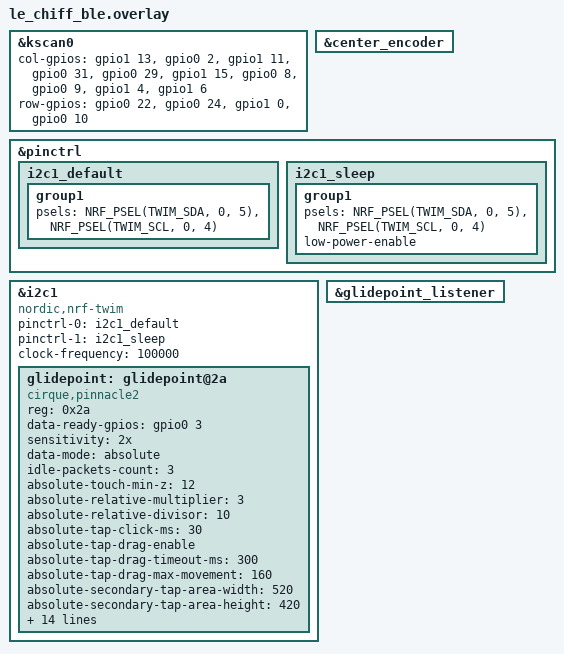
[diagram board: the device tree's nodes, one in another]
/*
 * Copyright (c) 2020 The ZMK Contributors
 *
 * SPDX-License-Identifier: MIT
 */

#include "le_chiff_ble.dtsi"
#include <behaviors/battery_history_request.dtsi>
#include <input/processors.dtsi>
#include <input/processors/runtime-input-processor.dtsi>

&kscan0 {
    col-gpios
        = <&gpio1 13 GPIO_ACTIVE_HIGH>
        , <&gpio0 2 GPIO_ACTIVE_HIGH>
        , <&gpio1 11 GPIO_ACTIVE_HIGH>
        , <&gpio0 31 GPIO_ACTIVE_HIGH>
        , <&gpio0 29 GPIO_ACTIVE_HIGH>
        , <&gpio1 15 GPIO_ACTIVE_HIGH>
        , <&gpio0 8 GPIO_ACTIVE_HIGH>
        , <&gpio0 9 GPIO_ACTIVE_HIGH>
        , <&gpio1 4 GPIO_ACTIVE_HIGH>
        , <&gpio1 6 GPIO_ACTIVE_HIGH>
        ;
    row-gpios
        = <&gpio0 22 (GPIO_ACTIVE_HIGH | GPIO_PULL_DOWN)>
        , <&gpio0 24 (GPIO_ACTIVE_HIGH | GPIO_PULL_DOWN)>
        , <&gpio1 0  (GPIO_ACTIVE_HIGH | GPIO_PULL_DOWN)>
        , <&gpio0 10 (GPIO_ACTIVE_HIGH | GPIO_PULL_DOWN)>
        ;
};

&center_encoder {
    status = "okay";
};

// === Cirque Pinnacle2 40mm Trackpad (I2C1) ===
// Uses I2C1 to avoid conflict with SPI0 display on GP0.20/GP0.17
// TODO: CONFIRM GPIO ASSIGNMENTS before building
// Suggested placeholders: SDA=GP0.5, SCL=GP0.4, DRDY=GP0.3
&pinctrl {
    i2c1_default: i2c1_default {
        group1 {
            psels = <NRF_PSEL(TWIM_SDA, 0, 5)>,
                <NRF_PSEL(TWIM_SCL, 0, 4)>;
        };
    };

    i2c1_sleep: i2c1_sleep {
        group1 {
            psels = <NRF_PSEL(TWIM_SDA, 0, 5)>,
                <NRF_PSEL(TWIM_SCL, 0, 4)>;
            low-power-enable;
        };
    };
};

&i2c1 {
    compatible = "nordic,nrf-twim";
    status = "okay";

    pinctrl-0 = <&i2c1_default>;
    pinctrl-1 = <&i2c1_sleep>;
    pinctrl-names = "default", "sleep";

    clock-frequency = <100000>;

    glidepoint: glidepoint@2a {
        compatible = "cirque,pinnacle2";
        reg = <0x2a>;
        status = "okay";
        data-ready-gpios = <&gpio0 3 GPIO_ACTIVE_HIGH>;
        sensitivity = "2x";
        data-mode = "absolute";
        idle-packets-count = <3>;
        absolute-touch-min-z = <12>;
        absolute-relative-multiplier = <3>;
        absolute-relative-divisor = <10>;
        absolute-tap-click-ms = <30>;
        absolute-tap-drag-enable;
        absolute-tap-drag-timeout-ms = <300>;
        absolute-tap-drag-max-movement = <160>;
        absolute-secondary-tap-area-width = <520>;
        absolute-secondary-tap-area-height = <420>;
        absolute-aux-tap-area-width = <0>;
        absolute-aux-tap-area-height = <0>;
        absolute-edge-motion-enable;
        absolute-edge-motion-zone = <80>;
        absolute-edge-motion-speed = <4>;
        absolute-edge-motion-interval-ms = <10>;
        absolute-edge-motion-start-ms = <120>;
        absolute-right-edge-scroll-enable;
        absolute-scroll-zone = <130>;
        absolute-scroll-divisor = <80>;
        startup-delay-ms = <1500>;
        primary-tap-enable;
        glide-extend-enable;
        invert-y;
    };
};

&glidepoint_listener {
    status = "okay";
};
